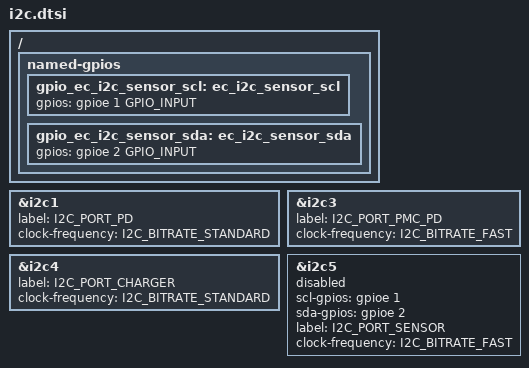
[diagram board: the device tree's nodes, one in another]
/* Copyright 2023 The ChromiumOS Authors
 * Use of this source code is governed by a BSD-style license that can be
 * found in the LICENSE file.
 */

&i2c1 {
	label = "I2C_PORT_PD";
	clock-frequency = <I2C_BITRATE_STANDARD>;
};

&i2c3 {
	label = "I2C_PORT_PMC_PD";
	clock-frequency = <I2C_BITRATE_FAST>;
};

&i2c4 {
	label = "I2C_PORT_CHARGER";
	clock-frequency = <I2C_BITRATE_STANDARD>;
};


/*
 * TODO: b/319267575 - [Brox Proto1] PP3300_S5 has leakage in Z1
 * Disable I2C sensor bus and configure pins as input.
 */
/delete-node/ &i2c_ec_i2c_sensor;
/ {
	named-gpios {
		gpio_ec_i2c_sensor_scl: ec_i2c_sensor_scl {
			gpios = <&gpioe 1 GPIO_INPUT>;
		};
		gpio_ec_i2c_sensor_sda: ec_i2c_sensor_sda {
			gpios = <&gpioe 2 GPIO_INPUT>;
		};
	};
};


&i2c5 {
	/* TODO: b/319267575 - [Brox Proto1] PP3300_S5 has leakage in Z1 */
	status = "disabled";

	scl-gpios = <&gpioe 1 0>;
	sda-gpios = <&gpioe 2 0>;

	label = "I2C_PORT_SENSOR";
	clock-frequency = <I2C_BITRATE_FAST>;
};
